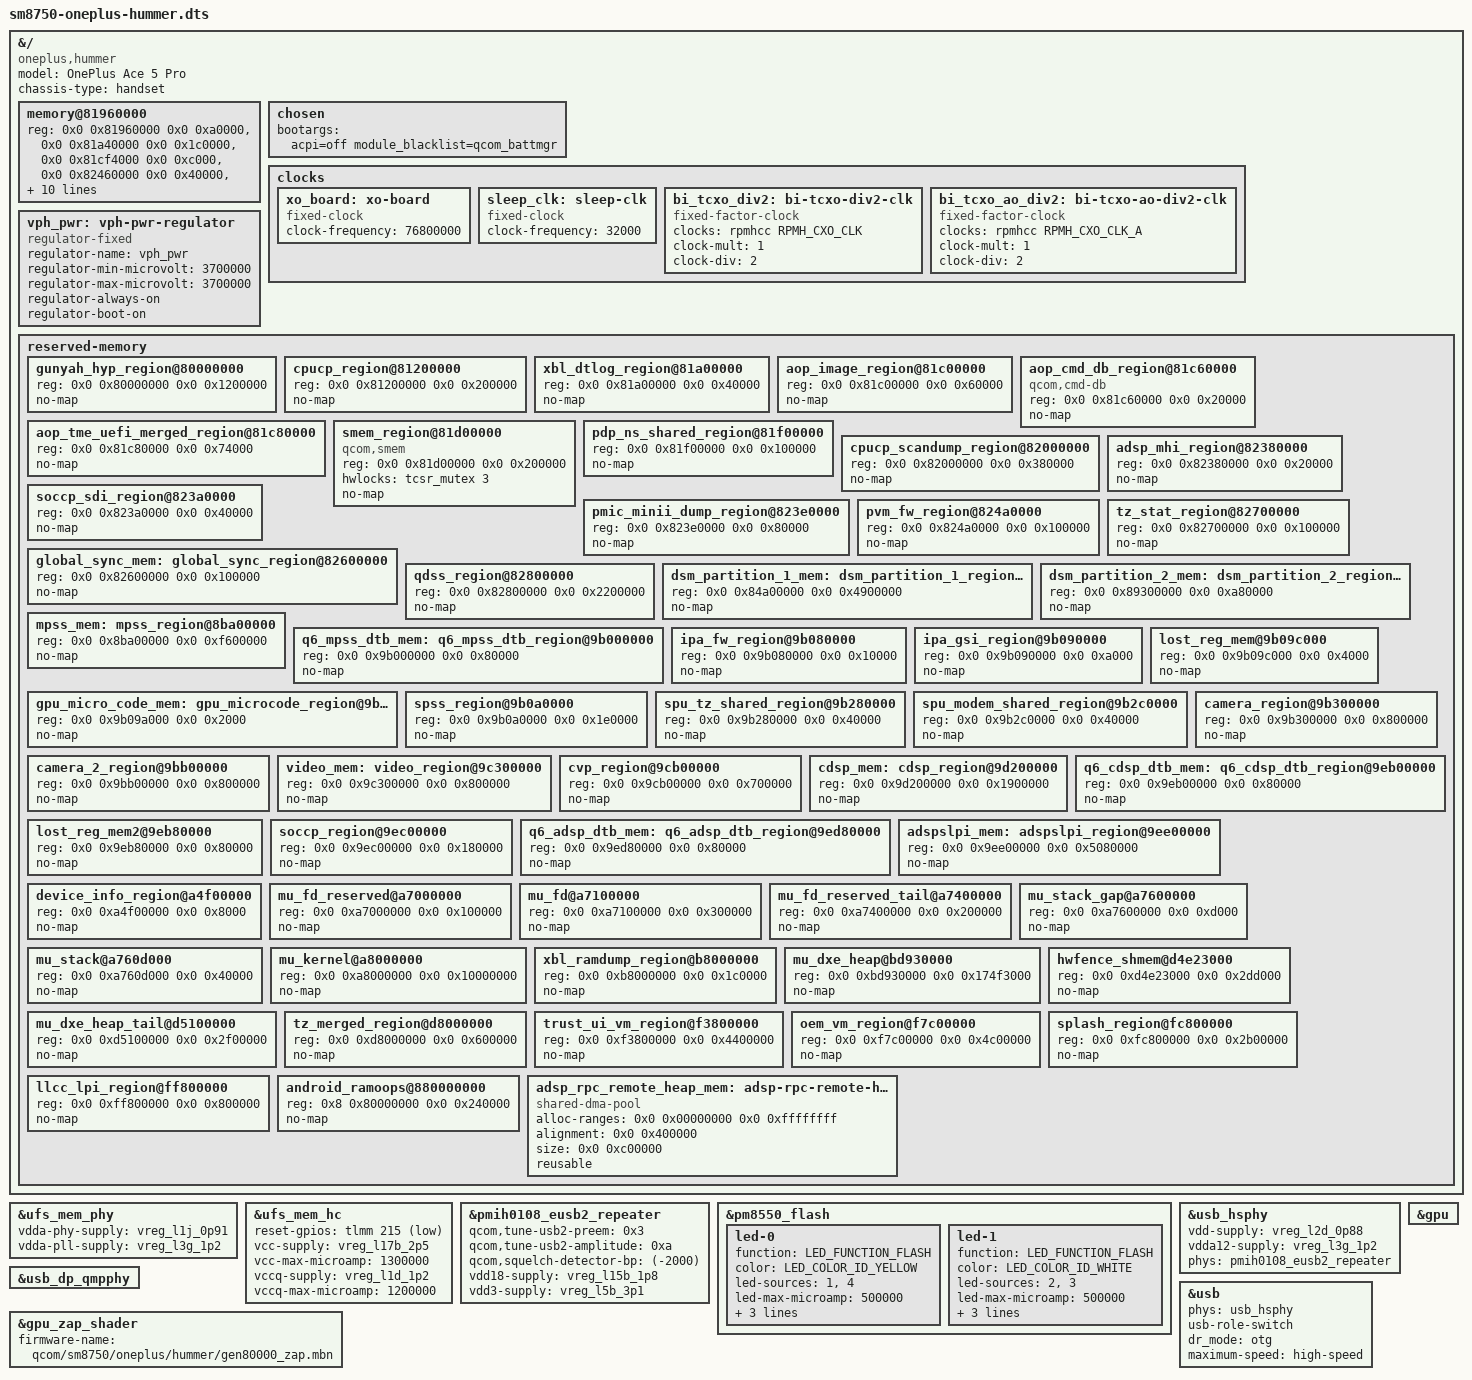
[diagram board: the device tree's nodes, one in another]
/dts-v1/;

/memreserve/ 0x00000000a764d000 0x00000000009b3000;
/memreserve/ 0x00000000bd930000 0x00000000174f3000;
/memreserve/ 0x00000000d5100000 0x0000000002f00000;

#include <dt-bindings/gpio/gpio.h>
#include <dt-bindings/leds/common.h>
#include <dt-bindings/regulator/qcom,rpmh-regulator.h>
#include "sm8750.dtsi"
#include "pm8010.dtsi"
#include "pm8550.dtsi"
#define PMK8550VE_SID 8
#include "pm8550ve.dtsi"
#include "pmd8028.dtsi"
#include "pmih0108.dtsi"
#include "pmk8550.dtsi"
#include "pmr735d_a.dtsi"
#include "sm8750-pmics.dtsi"
#include "sm8750-oneplus-hummer-pmics.dtsi"

&{/} {
	model = "OnePlus Ace 5 Pro";
	compatible = "oneplus,hummer", "qcom,sm8750";
	chassis-type = "handset";

	/delete-node/ memory@a0000000;
	/delete-node/ reserved-memory;

	memory@81960000 {
		device_type = "memory";
		reg = <0x0 0x81960000 0x0 0xa0000>,
			      <0x0 0x81a40000 0x0 0x1c0000>,
			      <0x0 0x81cf4000 0x0 0xc000>,
			      <0x0 0x82460000 0x0 0x40000>,
			      <0x0 0x82800000 0x0 0x2200000>,
			      <0x0 0x89d80000 0x0 0x1c80000>,
			      <0x0 0xa3e80000 0x0 0x14180000>,
			      <0x0 0xb81c0000 0x0 0x1cc63000>,
			      <0x0 0xd5100000 0x0 0x2f00000>,
			      <0x0 0xe3720000 0x0 0x1c0e0000>,
			      <0x8 0x80000000 0x0 0x2f6fd000>,
			      <0x8 0xb0000000 0x0 0x5500000>,
			      <0x8 0xc0000000 0x1 0x40000000>,
			      <0xa 0x00000000 0x2 0x00000000>;
	};

	chosen {
		bootargs = "acpi=off module_blacklist=qcom_battmgr";
	};

	clocks {
		xo_board: xo-board {
			compatible = "fixed-clock";
			clock-frequency = <76800000>;
			#clock-cells = <0>;
		};

		sleep_clk: sleep-clk {
			compatible = "fixed-clock";
			clock-frequency = <32000>;
			#clock-cells = <0>;
		};

		bi_tcxo_div2: bi-tcxo-div2-clk {
			compatible = "fixed-factor-clock";
			#clock-cells = <0>;
			clocks = <&rpmhcc RPMH_CXO_CLK>;
			clock-mult = <1>;
			clock-div = <2>;
		};

		bi_tcxo_ao_div2: bi-tcxo-ao-div2-clk {
			compatible = "fixed-factor-clock";
			#clock-cells = <0>;
			clocks = <&rpmhcc RPMH_CXO_CLK_A>;
			clock-mult = <1>;
			clock-div = <2>;
		};
	};

	vph_pwr: vph-pwr-regulator {
		compatible = "regulator-fixed";
		regulator-name = "vph_pwr";
		regulator-min-microvolt = <3700000>;
		regulator-max-microvolt = <3700000>;
		regulator-always-on;
		regulator-boot-on;
	};

	reserved-memory {
		#address-cells = <2>;
		#size-cells = <2>;
		ranges;

		gunyah_hyp_region@80000000 {
			reg = <0x0 0x80000000 0x0 0x1200000>;
			no-map;
		};

		cpucp_region@81200000 {
			reg = <0x0 0x81200000 0x0 0x200000>;
			no-map;
		};

		xbl_dtlog_region@81a00000 {
			reg = <0x0 0x81a00000 0x0 0x40000>;
			no-map;
		};

		aop_image_region@81c00000 {
			reg = <0x0 0x81c00000 0x0 0x60000>;
			no-map;
		};

		aop_cmd_db_region@81c60000 {
			compatible = "qcom,cmd-db";
			reg = <0x0 0x81c60000 0x0 0x20000>;
			no-map;
		};

		aop_tme_uefi_merged_region@81c80000 {
			reg = <0x0 0x81c80000 0x0 0x74000>;
			no-map;
		};

		smem_region@81d00000 {
			compatible = "qcom,smem";
			reg = <0x0 0x81d00000 0x0 0x200000>;
			hwlocks = <&tcsr_mutex 3>;
			no-map;
		};

		pdp_ns_shared_region@81f00000 {
			reg = <0x0 0x81f00000 0x0 0x100000>;
			no-map;
		};

		cpucp_scandump_region@82000000 {
			reg = <0x0 0x82000000 0x0 0x380000>;
			no-map;
		};

		adsp_mhi_region@82380000 {
			reg = <0x0 0x82380000 0x0 0x20000>;
			no-map;
		};

		soccp_sdi_region@823a0000 {
			reg = <0x0 0x823a0000 0x0 0x40000>;
			no-map;
		};

		pmic_minii_dump_region@823e0000 {
			reg = <0x0 0x823e0000 0x0 0x80000>;
			no-map;
		};

		pvm_fw_region@824a0000 {
			reg = <0x0 0x824a0000 0x0 0x100000>;
			no-map;
		};

		global_sync_mem: global_sync_region@82600000 {
			reg = <0x0 0x82600000 0x0 0x100000>;
			no-map;
		};

		tz_stat_region@82700000 {
			reg = <0x0 0x82700000 0x0 0x100000>;
			no-map;
		};

		qdss_region@82800000 {
			reg = <0x0 0x82800000 0x0 0x2200000>;
			no-map;
		};

		dsm_partition_1_mem: dsm_partition_1_region@84a00000 {
			reg = <0x0 0x84a00000 0x0 0x4900000>;
			no-map;
		};

		dsm_partition_2_mem: dsm_partition_2_region@89300000 {
			reg = <0x0 0x89300000 0x0 0xa80000>;
			no-map;
		};

		mpss_mem: mpss_region@8ba00000 {
			reg = <0x0 0x8ba00000 0x0 0xf600000>;
			no-map;
		};

		q6_mpss_dtb_mem: q6_mpss_dtb_region@9b000000 {
			reg = <0x0 0x9b000000 0x0 0x80000>;
			no-map;
		};

		ipa_fw_region@9b080000 {
			reg = <0x0 0x9b080000 0x0 0x10000>;
			no-map;
		};

		ipa_gsi_region@9b090000 {
			reg = <0x0 0x9b090000 0x0 0xa000>;
			no-map;
		};

		gpu_micro_code_mem: gpu_microcode_region@9b09a000 {
			reg = <0x0 0x9b09a000 0x0 0x2000>;
			no-map;
		};

		lost_reg_mem@9b09c000 {
			reg = <0x0 0x9b09c000 0x0 0x4000>;
			no-map;
		};

		spss_region@9b0a0000 {
			reg = <0x0 0x9b0a0000 0x0 0x1e0000>;
			no-map;
		};

		spu_tz_shared_region@9b280000 {
			reg = <0x0 0x9b280000 0x0 0x40000>;
			no-map;
		};

		spu_modem_shared_region@9b2c0000 {
			reg = <0x0 0x9b2c0000 0x0 0x40000>;
			no-map;
		};

		camera_region@9b300000 {
			reg = <0x0 0x9b300000 0x0 0x800000>;
			no-map;
		};

		camera_2_region@9bb00000 {
			reg = <0x0 0x9bb00000 0x0 0x800000>;
			no-map;
		};

		video_mem: video_region@9c300000 {
			reg = <0x0 0x9c300000 0x0 0x800000>;
			no-map;
		};

		cvp_region@9cb00000 {
			reg = <0x0 0x9cb00000 0x0 0x700000>;
			no-map;
		};

		cdsp_mem: cdsp_region@9d200000 {
			reg = <0x0 0x9d200000 0x0 0x1900000>;
			no-map;
		};

		q6_cdsp_dtb_mem: q6_cdsp_dtb_region@9eb00000 {
			reg = <0x0 0x9eb00000 0x0 0x80000>;
			no-map;
		};

		lost_reg_mem2@9eb80000 {
			reg = <0x0 0x9eb80000 0x0 0x80000>;
			no-map;
		};

		soccp_region@9ec00000 {
			reg = <0x0 0x9ec00000 0x0 0x180000>;
			no-map;
		};

		q6_adsp_dtb_mem: q6_adsp_dtb_region@9ed80000 {
			reg = <0x0 0x9ed80000 0x0 0x80000>;
			no-map;
		};

		adspslpi_mem: adspslpi_region@9ee00000 {
			reg = <0x0 0x9ee00000 0x0 0x5080000>;
			no-map;
		};

		device_info_region@a4f00000 {
			reg = <0x0 0xa4f00000 0x0 0x8000>;
			no-map;
		};

		mu_fd_reserved@a7000000 {
			reg = <0x0 0xa7000000 0x0 0x100000>;
			no-map;
		};

		mu_fd@a7100000 {
			reg = <0x0 0xa7100000 0x0 0x300000>;
			no-map;
		};

		mu_fd_reserved_tail@a7400000 {
			reg = <0x0 0xa7400000 0x0 0x200000>;
			no-map;
		};

		mu_stack_gap@a7600000 {
			reg = <0x0 0xa7600000 0x0 0xd000>;
			no-map;
		};

		mu_stack@a760d000 {
			reg = <0x0 0xa760d000 0x0 0x40000>;
			no-map;
		};

		mu_kernel@a8000000 {
			reg = <0x0 0xa8000000 0x0 0x10000000>;
			no-map;
		};

		xbl_ramdump_region@b8000000 {
			reg = <0x0 0xb8000000 0x0 0x1c0000>;
			no-map;
		};

		mu_dxe_heap@bd930000 {
			reg = <0x0 0xbd930000 0x0 0x174f3000>;
			no-map;
		};

		hwfence_shmem@d4e23000 {
			reg = <0x0 0xd4e23000 0x0 0x2dd000>;
			no-map;
		};

		mu_dxe_heap_tail@d5100000 {
			reg = <0x0 0xd5100000 0x0 0x2f00000>;
			no-map;
		};

		tz_merged_region@d8000000 {
			reg = <0x0 0xd8000000 0x0 0x600000>;
			no-map;
		};

		trust_ui_vm_region@f3800000 {
			reg = <0x0 0xf3800000 0x0 0x4400000>;
			no-map;
		};

		oem_vm_region@f7c00000 {
			reg = <0x0 0xf7c00000 0x0 0x4c00000>;
			no-map;
		};

		splash_region@fc800000 {
			reg = <0x0 0xfc800000 0x0 0x2b00000>;
			no-map;
		};

		llcc_lpi_region@ff800000 {
			reg = <0x0 0xff800000 0x0 0x800000>;
			no-map;
		};

		android_ramoops@880000000 {
			reg = <0x8 0x80000000 0x0 0x240000>;
			no-map;
		};

		adsp_rpc_remote_heap_mem: adsp-rpc-remote-heap {
			compatible = "shared-dma-pool";
			alloc-ranges = <0x0 0x00000000 0x0 0xffffffff>;
			alignment = <0x0 0x400000>;
			size = <0x0 0xc00000>;
			reusable;
		};
	};
};

&ufs_mem_phy {
	vdda-phy-supply = <&vreg_l1j_0p91>;
	vdda-pll-supply = <&vreg_l3g_1p2>;
	status = "okay";
};

&ufs_mem_hc {
	reset-gpios = <&tlmm 215 GPIO_ACTIVE_LOW>;
	vcc-supply = <&vreg_l17b_2p5>;
	vcc-max-microamp = <1300000>;
	vccq-supply = <&vreg_l1d_1p2>;
	vccq-max-microamp = <1200000>;
	status = "okay";
};

&pmih0108_eusb2_repeater {
	qcom,tune-usb2-preem = /bits/ 8 <0x3>;
	qcom,tune-usb2-amplitude = /bits/ 8 <0xa>;
	qcom,squelch-detector-bp = <(-2000)>;

	vdd18-supply = <&vreg_l15b_1p8>;
	vdd3-supply = <&vreg_l5b_3p1>;
	status = "okay";
};

&pm8550_flash {
	status = "okay";

	led-0 {
		function = LED_FUNCTION_FLASH;
		color = <LED_COLOR_ID_YELLOW>;
		led-sources = <1>, <4>;
		led-max-microamp = <500000>;
		flash-max-microamp = <2000000>;
		flash-max-timeout-us = <1280000>;
		function-enumerator = <0>;
	};

	led-1 {
		function = LED_FUNCTION_FLASH;
		color = <LED_COLOR_ID_WHITE>;
		led-sources = <2>, <3>;
		led-max-microamp = <500000>;
		flash-max-microamp = <2000000>;
		flash-max-timeout-us = <1280000>;
		function-enumerator = <1>;
	};
};

&usb_hsphy {
	vdd-supply = <&vreg_l2d_0p88>;
	vdda12-supply = <&vreg_l3g_1p2>;
	phys = <&pmih0108_eusb2_repeater>;
	status = "okay";
};

&usb_dp_qmpphy {
	status = "okay";
};

&usb {
	phys = <&usb_hsphy>;
	phy-names = "usb2-phy";
	usb-role-switch;
	dr_mode = "otg";
	maximum-speed = "high-speed";
	status = "okay";
};

#include "sm8750-oneplus-hummer-bringup.dtsi"
#include "sm8750-oneplus-hummer-display.dtsi"

&gpu {
	status = "okay";
};

&gpu_zap_shader {
	firmware-name = "qcom/sm8750/oneplus/hummer/gen80000_zap.mbn";
};
